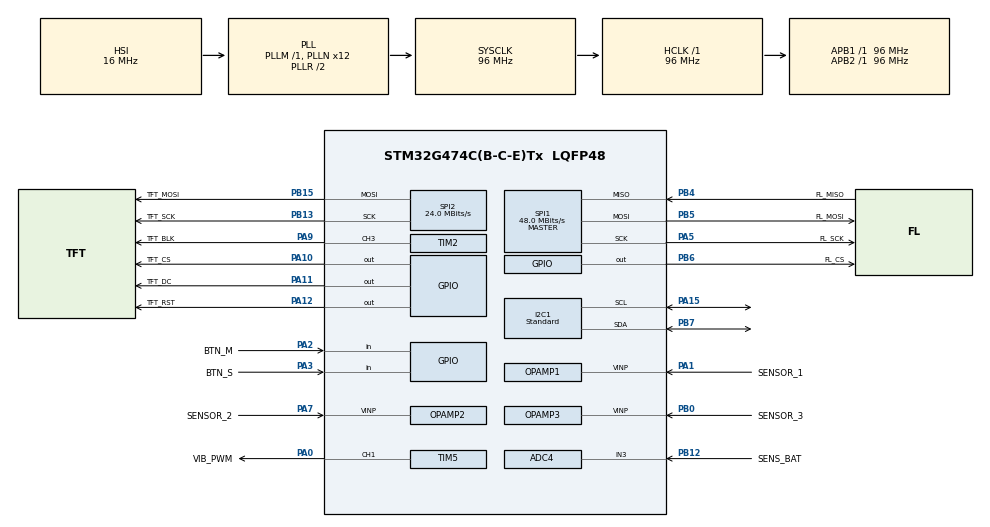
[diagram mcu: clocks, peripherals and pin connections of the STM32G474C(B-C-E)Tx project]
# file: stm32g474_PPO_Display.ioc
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ADC1.Channel-2\#ChannelRegularConversion=ADC_CHANNEL_VOPAMP1
ADC1.ContinuousConvMode=ENABLE
ADC1.DMAContinuousRequests=ENABLE
ADC1.EOCSelection=ADC_EOC_SEQ_CONV
ADC1.NbrOfConversionFlag=1
ADC1.OffsetNumber-2\#ChannelRegularConversion=ADC_OFFSET_NONE
ADC1.OversamplingMode=ENABLE
ADC1.Rank-2\#ChannelRegularConversion=1
ADC1.Ratio=ADC_OVERSAMPLING_RATIO_16
ADC1.RightBitShift=ADC_RIGHTBITSHIFT_4
ADC1.SamplingTime-2\#ChannelRegularConversion=ADC_SAMPLETIME_247CYCLES_5
ADC1.master=1
ADC2.Channel-0\#ChannelRegularConversion=ADC_CHANNEL_VOPAMP2
ADC2.ContinuousConvMode=ENABLE
ADC2.DMAContinuousRequests=ENABLE
ADC2.NbrOfConversionFlag=1
ADC2.OffsetNumber-0\#ChannelRegularConversion=ADC_OFFSET_NONE
ADC2.OversamplingMode=ENABLE
ADC2.Rank-0\#ChannelRegularConversion=1
ADC2.Ratio=ADC_OVERSAMPLING_RATIO_16
ADC2.RightBitShift=ADC_RIGHTBITSHIFT_4
ADC2.SamplingTime-0\#ChannelRegularConversion=ADC_SAMPLETIME_247CYCLES_5
ADC3.Channel-0\#ChannelRegularConversion=ADC_CHANNEL_VOPAMP3_ADC3
ADC3.ContinuousConvMode=ENABLE
ADC3.DMAContinuousRequests=ENABLE
ADC3.EOCSelection=ADC_EOC_SEQ_CONV
ADC3.NbrOfConversionFlag=1
ADC3.OffsetNumber-0\#ChannelRegularConversion=ADC_OFFSET_NONE
ADC3.OversamplingMode=ENABLE
ADC3.Rank-0\#ChannelRegularConversion=1
ADC3.Ratio=ADC_OVERSAMPLING_RATIO_16
ADC3.RightBitShift=ADC_RIGHTBITSHIFT_4
ADC3.SamplingTime-0\#ChannelRegularConversion=ADC_SAMPLETIME_247CYCLES_5
ADC3.master=1
ADC4.Channel-0\#ChannelRegularConversion=ADC_CHANNEL_VREFINT
ADC4.Channel-1\#ChannelRegularConversion=ADC_CHANNEL_3
ADC4.ContinuousConvMode=ENABLE
ADC4.DMAContinuousRequests=ENABLE
ADC4.EOCSelection=ADC_EOC_SEQ_CONV
ADC4.NbrOfConversion=2
ADC4.NbrOfConversionFlag=1
ADC4.OffsetNumber-0\#ChannelRegularConversion=ADC_OFFSET_NONE
ADC4.OffsetNumber-1\#ChannelRegularConversion=ADC_OFFSET_NONE
ADC4.OversamplingMode=ENABLE
ADC4.Rank-0\#ChannelRegularConversion=1
ADC4.Rank-1\#ChannelRegularConversion=2
ADC4.Ratio=ADC_OVERSAMPLING_RATIO_16
ADC4.RightBitShift=ADC_RIGHTBITSHIFT_4
ADC4.SamplingTime-0\#ChannelRegularConversion=ADC_SAMPLETIME_247CYCLES_5
ADC4.SamplingTime-1\#ChannelRegularConversion=ADC_SAMPLETIME_247CYCLES_5
Dma.ADC1.1.Direction=DMA_PERIPH_TO_MEMORY
Dma.ADC1.1.EventEnable=DISABLE
Dma.ADC1.1.Instance=DMA1_Channel4
Dma.ADC1.1.MemDataAlignment=DMA_MDATAALIGN_HALFWORD
Dma.ADC1.1.MemInc=DMA_MINC_ENABLE
Dma.ADC1.1.Mode=DMA_CIRCULAR
Dma.ADC1.1.PeriphDataAlignment=DMA_PDATAALIGN_HALFWORD
Dma.ADC1.1.PeriphInc=DMA_PINC_DISABLE
Dma.ADC1.1.Polarity=HAL_DMAMUX_REQ_GEN_RISING
Dma.ADC1.1.Priority=DMA_PRIORITY_LOW
Dma.ADC1.1.RequestNumber=1
Dma.ADC1.1.SignalID=NONE
Dma.ADC1.1.SyncEnable=DISABLE
Dma.ADC1.1.SyncPolarity=HAL_DMAMUX_SYNC_NO_EVENT
Dma.ADC1.1.SyncRequestNumber=1
Dma.ADC1.1.SyncSignalID=NONE
Dma.ADC2.2.Direction=DMA_PERIPH_TO_MEMORY
Dma.ADC2.2.EventEnable=DISABLE
Dma.ADC2.2.Instance=DMA1_Channel5
Dma.ADC2.2.MemDataAlignment=DMA_MDATAALIGN_HALFWORD
Dma.ADC2.2.MemInc=DMA_MINC_ENABLE
Dma.ADC2.2.Mode=DMA_CIRCULAR
Dma.ADC2.2.PeriphDataAlignment=DMA_PDATAALIGN_HALFWORD
Dma.ADC2.2.PeriphInc=DMA_PINC_DISABLE
Dma.ADC2.2.Polarity=HAL_DMAMUX_REQ_GEN_RISING
Dma.ADC2.2.Priority=DMA_PRIORITY_LOW
Dma.ADC2.2.RequestNumber=1
Dma.ADC2.2.SignalID=NONE
Dma.ADC2.2.SyncEnable=DISABLE
Dma.ADC2.2.SyncPolarity=HAL_DMAMUX_SYNC_NO_EVENT
Dma.ADC2.2.SyncRequestNumber=1
Dma.ADC2.2.SyncSignalID=NONE
Dma.ADC3.3.Direction=DMA_PERIPH_TO_MEMORY
Dma.ADC3.3.EventEnable=DISABLE
Dma.ADC3.3.Instance=DMA1_Channel6
Dma.ADC3.3.MemDataAlignment=DMA_MDATAALIGN_HALFWORD
Dma.ADC3.3.MemInc=DMA_MINC_ENABLE
Dma.ADC3.3.Mode=DMA_CIRCULAR
Dma.ADC3.3.PeriphDataAlignment=DMA_PDATAALIGN_HALFWORD
Dma.ADC3.3.PeriphInc=DMA_PINC_DISABLE
Dma.ADC3.3.Polarity=HAL_DMAMUX_REQ_GEN_RISING
Dma.ADC3.3.Priority=DMA_PRIORITY_LOW
Dma.ADC3.3.RequestNumber=1
Dma.ADC3.3.SignalID=NONE
Dma.ADC3.3.SyncEnable=DISABLE
Dma.ADC3.3.SyncPolarity=HAL_DMAMUX_SYNC_NO_EVENT
Dma.ADC3.3.SyncRequestNumber=1
Dma.ADC3.3.SyncSignalID=NONE
Dma.ADC4.4.Direction=DMA_PERIPH_TO_MEMORY
Dma.ADC4.4.EventEnable=DISABLE
Dma.ADC4.4.Instance=DMA1_Channel7
Dma.ADC4.4.MemDataAlignment=DMA_MDATAALIGN_HALFWORD
Dma.ADC4.4.MemInc=DMA_MINC_ENABLE
Dma.ADC4.4.Mode=DMA_CIRCULAR
Dma.ADC4.4.PeriphDataAlignment=DMA_PDATAALIGN_HALFWORD
Dma.ADC4.4.PeriphInc=DMA_PINC_DISABLE
Dma.ADC4.4.Polarity=HAL_DMAMUX_REQ_GEN_RISING
Dma.ADC4.4.Priority=DMA_PRIORITY_LOW
Dma.ADC4.4.RequestNumber=1
Dma.ADC4.4.SignalID=NONE
Dma.ADC4.4.SyncEnable=DISABLE
Dma.ADC4.4.SyncPolarity=HAL_DMAMUX_SYNC_NO_EVENT
Dma.ADC4.4.SyncRequestNumber=1
Dma.ADC4.4.SyncSignalID=NONE
Dma.Request0=SPI2_TX
Dma.Request1=ADC1
Dma.Request2=ADC2
Dma.Request3=ADC3
Dma.Request4=ADC4
Dma.SPI2_TX.0.Direction=DMA_MEMORY_TO_PERIPH
Dma.SPI2_TX.0.EventEnable=DISABLE
Dma.SPI2_TX.0.Instance=DMA1_Channel1
Dma.SPI2_TX.0.MemDataAlignment=DMA_MDATAALIGN_BYTE
Dma.SPI2_TX.0.MemInc=DMA_MINC_ENABLE
Dma.SPI2_TX.0.Mode=DMA_NORMAL
Dma.SPI2_TX.0.PeriphDataAlignment=DMA_PDATAALIGN_BYTE
Dma.SPI2_TX.0.PeriphInc=DMA_PINC_DISABLE
Dma.SPI2_TX.0.Polarity=HAL_DMAMUX_REQ_GEN_RISING
Dma.SPI2_TX.0.Priority=DMA_PRIORITY_MEDIUM
Dma.SPI2_TX.0.RequestNumber=1
Dma.SPI2_TX.0.SignalID=NONE
Dma.SPI2_TX.0.SyncEnable=DISABLE
Dma.SPI2_TX.0.SyncPolarity=HAL_DMAMUX_SYNC_NO_EVENT
Dma.SPI2_TX.0.SyncRequestNumber=1
Dma.SPI2_TX.0.SyncSignalID=NONE
I2C1.Analog_Filter=I2C_ANALOGFILTER_ENABLE
I2C1.I2C_Coeff_DF=0
I2C1.I2C_Speed_Mode=I2C_Standard
I2C1.Speed=100
I2C1.Timing=0x20B17DB6
IWDG.Prescaler=IWDG_PRESCALER_64
IWDG.Reload=2999
Mcu.Family=STM32G4
Mcu.Name=STM32G474C(B-C-E)Tx
Mcu.Package=LQFP48
NVIC.ADC1_2_IRQn=true\:0\:0\:false\:false\:true\:true\:true\:true
NVIC.ADC3_IRQn=true\:0\:0\:false\:false\:true\:true\:true\:true
NVIC.ADC4_IRQn=true\:0\:0\:false\:false\:true\:true\:true\:true
NVIC.DMA1_Channel1_IRQn=true\:0\:0\:false\:false\:true\:false\:true\:true
NVIC.DMA1_Channel4_IRQn=true\:0\:0\:false\:false\:true\:false\:true\:true
NVIC.DMA1_Channel5_IRQn=true\:0\:0\:false\:false\:true\:false\:true\:true
NVIC.DMA1_Channel6_IRQn=true\:0\:0\:false\:false\:true\:false\:true\:true
NVIC.DMA1_Channel7_IRQn=true\:0\:0\:false\:false\:true\:false\:true\:true
NVIC.I2C1_ER_IRQn=true\:1\:0\:true\:false\:true\:true\:true\:true
NVIC.I2C1_EV_IRQn=true\:1\:0\:true\:false\:true\:true\:true\:true
NVIC.PriorityGroup=NVIC_PRIORITYGROUP_4
NVIC.SPI2_IRQn=true\:0\:0\:false\:false\:true\:true\:true\:true
NVIC.TIM6_DAC_IRQn=true\:0\:0\:false\:false\:true\:true\:true\:true
OPAMP1.PgaGain=OPAMP_PGA_GAIN_16_OR_MINUS_15
OPAMP2.PgaGain=OPAMP_PGA_GAIN_16_OR_MINUS_15
OPAMP3.PgaGain=OPAMP_PGA_GAIN_16_OR_MINUS_15
PA0.GPIO_Label=VIB_PWM
PA0.GPIO_Speed=GPIO_SPEED_FREQ_VERY_HIGH
PA0.Signal=S_TIM5_CH1
PA1.GPIO_Label=SENSOR_1
PA1.Mode=PGA_Internally_Connected
PA1.Signal=OPAMP1_VINP
PA10.GPIO_Label=TFT_CS
PA10.GPIO_Speed=GPIO_SPEED_FREQ_VERY_HIGH
PA10.PinState=GPIO_PIN_SET
PA10.Signal=GPIO_Output
PA11.GPIO_Label=TFT_DC
PA11.GPIO_Speed=GPIO_SPEED_FREQ_VERY_HIGH
PA11.PinState=GPIO_PIN_SET
PA11.Signal=GPIO_Output
PA12.GPIO_Label=TFT_RST
PA12.GPIO_PuPd=GPIO_PULLUP
PA12.GPIO_Speed=GPIO_SPEED_FREQ_VERY_HIGH
PA12.PinState=GPIO_PIN_SET
PA12.Signal=GPIO_Output
PA13.Mode=Serial_Wire
PA13.Signal=SYS_JTMS-SWDIO
PA14.Mode=Serial_Wire
PA14.Signal=SYS_JTCK-SWCLK
PA15.GPIO_Mode=GPIO_MODE_AF_OD
PA15.GPIO_Pu=GPIO_NOPULL
PA15.GPIO_Speed=GPIO_SPEED_FREQ_LOW
PA15.Mode=I2C
PA15.Signal=I2C1_SCL
PA2.GPIO_Label=BTN_M
PA2.GPIO_Mode=GPIO_MODE_INPUT
PA2.GPIO_PuPd=GPIO_PULLDOWN
PA2.Signal=GPIO_Input
PA3.GPIO_Label=BTN_S
PA3.GPIO_PuPd=GPIO_PULLDOWN
PA3.Signal=GPIO_Input
PA5.GPIO_Label=FL_SCK
PA5.GPIO_Speed=GPIO_SPEED_FREQ_VERY_HIGH
PA5.Mode=Full_Duplex_Master
PA5.Signal=SPI1_SCK
PA7.GPIO_Label=SENSOR_2
PA7.Mode=PGA_Internally_Connected
PA7.Signal=OPAMP2_VINP
PA9.GPIO_Label=TFT_BLK
PA9.GPIO_Speed=GPIO_SPEED_FREQ_VERY_HIGH
PA9.Signal=S_TIM2_CH3
PB0.GPIO_Label=SENSOR_3
PB0.Mode=PGA_Internally_Connected
PB0.Signal=OPAMP3_VINP
PB12.GPIO_Label=SENS_BAT
PB12.Mode=IN3-Single-Ended
PB12.Signal=ADC4_IN3
PB13.GPIO_Label=TFT_SCK
PB13.GPIO_PuPd=GPIO_PULLDOWN
PB13.GPIO_Speed=GPIO_SPEED_FREQ_VERY_HIGH
PB13.Mode=TX_Only_Simplex_Unidirect_Master
PB13.Signal=SPI2_SCK
PB15.GPIO_Label=TFT_MOSI
PB15.GPIO_PuPd=GPIO_PULLUP
PB15.GPIO_Speed=GPIO_SPEED_FREQ_VERY_HIGH
PB15.Mode=TX_Only_Simplex_Unidirect_Master
PB15.Signal=SPI2_MOSI
PB4.GPIO_Label=FL_MISO
PB4.GPIO_Speed=GPIO_SPEED_FREQ_VERY_HIGH
PB4.Mode=Full_Duplex_Master
PB4.Signal=SPI1_MISO
PB5.GPIO_Label=FL_MOSI
PB5.GPIO_Speed=GPIO_SPEED_FREQ_VERY_HIGH
PB5.Mode=Full_Duplex_Master
PB5.Signal=SPI1_MOSI
PB6.GPIO_Label=FL_CS
PB6.GPIO_PuPd=GPIO_PULLUP
PB6.GPIO_Speed=GPIO_SPEED_FREQ_VERY_HIGH
PB6.PinState=GPIO_PIN_SET
PB6.Signal=GPIO_Output
PB7.GPIO_FM7=__NULL
PB7.GPIO_Mode=GPIO_MODE_AF_OD
PB7.GPIO_Pu=GPIO_NOPULL
PB7.GPIO_Speed=GPIO_SPEED_FREQ_LOW
PB7.Mode=I2C
PB7.Signal=I2C1_SDA
ProjectManager.HeapSize=0x200
ProjectManager.StackSize=0x400
ProjectManager.TargetToolchain=STM32CubeIDE
RCC.ADC12Freq_Value=96000000
RCC.ADC345Freq_Value=96000000
RCC.AHBFreq_Value=96000000
RCC.APB1Freq_Value=96000000
RCC.APB1TimFreq_Value=96000000
RCC.APB2Freq_Value=96000000
RCC.APB2TimFreq_Value=96000000
RCC.CortexFreq_Value=96000000
RCC.EXTERNAL_CLOCK_VALUE=12288000
RCC.HCLKFreq_Value=96000000
RCC.HSE_VALUE=8000000
RCC.HSI48_VALUE=48000000
RCC.HSI_VALUE=16000000
RCC.LSE_VALUE=32768
RCC.PLLN=12
RCC.SYSCLKFreq_VALUE=96000000
RCC.SYSCLKSource=RCC_SYSCLKSOURCE_PLLCLK
RCC.USBFreq_Value=96000000
RCC.VCOOutputFreq_Value=192000000
SH.S_TIM2_CH3.0=TIM2_CH3,PWM Generation3 CH3
SH.S_TIM5_CH1.0=TIM5_CH1,PWM Generation1 CH1
SPI1.BaudRatePrescaler=SPI_BAUDRATEPRESCALER_2
SPI1.CLKPhase=SPI_PHASE_2EDGE
SPI1.CLKPolarity=SPI_POLARITY_HIGH
SPI1.CalculateBaudRate=48.0 MBits/s
SPI1.DataSize=SPI_DATASIZE_8BIT
SPI1.Direction=SPI_DIRECTION_2LINES
SPI1.Mode=SPI_MODE_MASTER
SPI1.VirtualType=VM_MASTER
SPI2.BaudRatePrescaler=SPI_BAUDRATEPRESCALER_4
SPI2.CLKPhase=SPI_PHASE_2EDGE
SPI2.CLKPolarity=SPI_POLARITY_HIGH
SPI2.CalculateBaudRate=24.0 MBits/s
SPI2.DataSize=SPI_DATASIZE_8BIT
SPI2.Direction=SPI_DIRECTION_2LINES
SPI2.Mode=SPI_MODE_MASTER
SPI2.VirtualType=VM_MASTER
TIM2.AutoReloadPreload=TIM_AUTORELOAD_PRELOAD_ENABLE
TIM2.Channel-PWM\ Generation3\ CH3=TIM_CHANNEL_3
TIM2.PeriodNoDither=4799
TIM5.Channel-PWM\ Generation1\ CH1=TIM_CHANNEL_1
TIM6.AutoReloadPreload=TIM_AUTORELOAD_PRELOAD_ENABLE
TIM6.PeriodNoDither=65535
TIM6.Prescaler=95
VP_ADC1_OPAMP_INTERNAL1.Mode=IN-OPAMP1
VP_ADC2_OPAMP_INTERNAL2.Mode=IN-OPAMP2
VP_ADC3_OPAMP_INTERNAL3.Mode=IN-OPAMP3
VP_ADC4_Vref_Input.Mode=IN-Vrefint
VP_IWDG_VS_IWDG.Mode=IWDG_Activate
VP_SYS_VS_DBSignals.Mode=DisableDeadBatterySignals
VP_TIM1_VS_ClockSourceINT.Mode=Internal
VP_TIM2_VS_ClockSourceINT.Mode=Internal
VP_TIM3_VS_ClockSourceINT.Mode=Internal
VP_TIM5_VS_ClockSourceINT.Mode=Internal
VP_TIM6_VS_ClockSourceINT.Mode=Enable_Timer
VREF+.Mode=InternalMode
VREF+.Signal=VREFBUF_OUT
board=custom

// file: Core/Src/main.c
/* USER CODE BEGIN Header */
/**
  ******************************************************************************
  * @file           : main.c
  * @brief          : Main program body
  ******************************************************************************
  * @attention
  *
  * Copyright (c) 2026 STMicroelectronics.
  * All rights reserved.
  *
  * This software is licensed under terms that can be found in the LICENSE file
  * in the root directory of this software component.
  * If no LICENSE file comes with this software, it is provided AS-IS.
  *
  ******************************************************************************
  */
/* USER CODE END Header */
#include "main.h"

/* USER CODE BEGIN Includes */
#include <stdatomic.h>
#include <stdbool.h>
#include "stm32g4xx_ll_adc.h"
#include "stm32g4xx.h"
#include "sensor.h"
#include "lvgl.h"
#include "st7789v.h"
#include "screen_manager.h"
#include "button.h"
#include "flash_storage.h"
#include "settings_storage.h"
#include "ext_flash_storage.h"
#include "drift_tracker.h"
#include "ms5837.h"
#include "w25q128.h"
#include "warning.h"
#include "dive_log.h"

/* USER CODE END Includes */

/* USER CODE BEGIN PTD */

// Display configuration (landscape orientation)
#define LCD_H_RES       320
#define LCD_V_RES       240
#define DISP_BUF_LINES  20  // Number of lines in partial refresh buffer

// LVGL display buffer - single buffer for partial refresh mode
// RGB565 = 2 bytes per pixel, 10 lines = 320 * 10 * 2 = 6400 bytes
static lv_color_t disp_buf1[LCD_H_RES * DISP_BUF_LINES] = {0};
static lv_color_t disp_buf2[LCD_H_RES * DISP_BUF_LINES] = {0};

// LVGL v8 display driver structures (must be global for ISR access from other files)
static lv_disp_draw_buf_t disp_draw_buf;
lv_disp_drv_t disp_drv;  // Non-static so ISR can access it

static volatile uint16_t ADC1_VAL[1];   // SENSOR1 via VOPAMP1
static volatile uint16_t ADC2_VAL[1];   // SENSOR2 via VOPAMP2
static volatile uint16_t ADC3_VAL[1];   // SENSOR3 via VOPAMP3
static volatile uint16_t ADC4_VAL[2];   // [0]=VREFINT  [1]=BAT (PB12)
static volatile atomic_bool g_adc1_new = false;
static volatile atomic_bool g_adc2_new = false;
static volatile atomic_bool g_adc3_new = false;
static volatile atomic_bool g_adc4_new = false;

// Elapsed time counter (seconds since boot)
uint32_t g_elapsed_time_sec = 0;
/* Bottom timer start depth in mm. 1000 mm = 1 m. Change for bench testing. */
#define BOTTOM_TIMER_START_DEPTH_MM  1000

static volatile uint32_t g_ms = 0; // ms since boot (from 1kHz tick)
static bool g_debugger_connected = false; // cached once at boot; DHCSR doesn't change at runtime

static volatile atomic_bool g_flag_1hz = false;
static volatile atomic_bool g_flag_5ms = false;
static volatile atomic_bool g_flag_20ms = false;
static volatile atomic_bool g_flag_10s = false;  // NEW: 10-second flag for drift tracking

/**
 * Gamma 2.2 Lookup Table for Backlight PWM
 * Clock: 48 MHz | Prescaler: 0 | ARR: 4799 (10 kHz PWM)
 * Index 0 = OFF, Index 1 = 10% ... Index 10 = 100%
 * Provides perceptually linear brightness control
 */
const uint16_t backlight_gamma_lut[11] = {
      0,   // 0%   (OFF)
     30,   // 10%
    139,   // 20%
    339,   // 30%
    639,   // 40%
   1044,   // 50%
   1561,   // 60%
   2190,   // 70%
   2937,   // 80%
   3808,   // 90%
   4799    // 100% (MAX)
};

uint32_t vref_effective_mv = 3300;     // == VDDA in mV

// Debug: Store VREFINT raw reading for troubleshooting
uint16_t vrefint_raw_debug = 0;

// MS5837 pressure sensor calibration and data
static ms5837_calib_t ms5837_calib;  // Factory calibration coefficients
static ms5837_data_t ms5837_data;    // Latest pressure/temperature measurement
static volatile bool ms5837_initialized = false;  // Initialization status flag
static bool ms5837_surface_set = false;           // True after first reading captures actual ambient

/* MS5837 DMA-driven measurement FSM */
typedef enum {
    MS5837_FSM_IDLE = 0,
    MS5837_FSM_D2_CONV_TX,   /* D2 conversion command TX in progress */
    MS5837_FSM_WAIT_D2,
    MS5837_FSM_D2_READ_TX,
    MS5837_FSM_D2_READ_RX,
    MS5837_FSM_D1_CMD_TX,
    MS5837_FSM_WAIT_D1,
    MS5837_FSM_D1_READ_TX,
    MS5837_FSM_D1_READ_RX,
    MS5837_FSM_CALCULATE,
} ms5837_fsm_t;

static volatile ms5837_fsm_t  ms5837_fsm        = MS5837_FSM_IDLE;
static volatile uint32_t      ms5837_conv_start = 0;
static volatile uint32_t      ms5837_raw_D1     = 0;
static volatile uint32_t      ms5837_raw_D2     = 0;
static volatile uint32_t      ms5837_last_meas  = 0;
/* Static buffers required: DMA accesses them after function returns */
static uint8_t       ms5837_tx_buf[1]  = {0};
static uint8_t       ms5837_rx_buf[3]  = {0, 0, 0};

/* USER CODE END PTD */

ADC_HandleTypeDef hadc1;
ADC_HandleTypeDef hadc2;
ADC_HandleTypeDef hadc3;
ADC_HandleTypeDef hadc4;
DMA_HandleTypeDef hdma_adc1;
DMA_HandleTypeDef hdma_adc2;
DMA_HandleTypeDef hdma_adc3;
DMA_HandleTypeDef hdma_adc4;

I2C_HandleTypeDef hi2c1;

IWDG_HandleTypeDef hiwdg;

OPAMP_HandleTypeDef hopamp1;
OPAMP_HandleTypeDef hopamp2;
OPAMP_HandleTypeDef hopamp3;

SPI_HandleTypeDef hspi1;
SPI_HandleTypeDef hspi2;
DMA_HandleTypeDef hdma_spi2_tx;

TIM_HandleTypeDef htim1;
TIM_HandleTypeDef htim2;
TIM_HandleTypeDef htim3;
TIM_HandleTypeDef htim5;
TIM_HandleTypeDef htim6;

void SystemClock_Config(void);
static void MX_GPIO_Init(void);
static void MX_DMA_Init(void);
static void MX_ADC1_Init(void);
static void MX_ADC2_Init(void);
static void MX_ADC3_Init(void);
static void MX_ADC4_Init(void);
static void MX_I2C1_Init(void);
static void MX_OPAMP1_Init(void);
static void MX_OPAMP2_Init(void);
static void MX_OPAMP3_Init(void);
static void MX_SPI1_Init(void);
static void MX_SPI2_Init(void);
static void MX_TIM2_Init(void);
static void MX_TIM5_Init(void);
static void MX_TIM1_Init(void);
static void MX_TIM6_Init(void);
static void MX_TIM3_Init(void);
static void MX_IWDG_Init(void);
/* USER CODE BEGIN PFP */
void vibro_motor_test(void);

static void scheduler_tick_1kHz(void);
static void scheduler_tick_5ms(void);
static void scheduler_tick_20ms(void);
static void scheduler_tick_10s(void);

void system_shutdown(void);  // Power management

static bool emulate_profile = false;
static bool emulate_descend = true;
static int8_t emulate_depth = 0;

/* USER CODE END PFP */

/* USER CODE BEGIN 0 */

uint8_t isDebuggerConnected(void) {
    if (CoreDebug->DHCSR & CoreDebug_DHCSR_C_DEBUGEN_Msk) {
        return 1; // Debugger is attached
    }
    return 0; // Running standalone
}

void HAL_TIM_PeriodElapsedCallback(TIM_HandleTypeDef *htim) {
	if (htim->Instance == TIM6) {
		scheduler_tick_1kHz();
		scheduler_tick_5ms();
		scheduler_tick_20ms();
		scheduler_tick_10s();  // NEW: 10-second scheduler for drift tracking
	}
}

static void scheduler_tick_5ms(void){
		static uint32_t t1 = 0;
		if ((g_ms - t1) >= 5) {
			t1 = g_ms;
			atomic_store(&g_flag_5ms, true);
		}
}

static void scheduler_tick_20ms(void) {
	static uint32_t t = 0;
	if ((g_ms - t) >= 20) {
		t = g_ms;
		atomic_store(&g_flag_20ms, true);
	}
}

static void scheduler_tick_1kHz(void) {
	g_ms++;

	// 1 Hz: every 1000 ms
	static uint32_t t1 = 0;
	if ((g_ms - t1) >= 1000) {
		t1 = g_ms;
		atomic_store(&g_flag_1hz, true);
	}
}

static void scheduler_tick_10s(void) {
	static uint32_t t = 0;
	if ((g_ms - t) >= 10000) {  // 10 seconds = 10000 ms
		t = g_ms;
		atomic_store(&g_flag_10s, true);
	}
}

void HAL_ADC_ConvCpltCallback(ADC_HandleTypeDef *hadc) {
    if (hadc->Instance == ADC1) atomic_store(&g_adc1_new, true);
    if (hadc->Instance == ADC2) atomic_store(&g_adc2_new, true);
    if (hadc->Instance == ADC3) atomic_store(&g_adc3_new, true);
    if (hadc->Instance == ADC4) atomic_store(&g_adc4_new, true);
}

void HAL_SPI_TxCpltCallback(SPI_HandleTypeDef *hspi)
{
    if (hspi->Instance == SPI2) {
    //    HAL_GPIO_WritePin(LCD_CS_GPIO_Port, LCD_CS_Pin, GPIO_PIN_SET);
     //   my_disp_bus_busy = 0;

        // v8 API: pass driver struct pointer
        lv_disp_flush_ready(&disp_drv);
    }
}

/**
 * @brief System shutdown - Stop peripherals and enter Stop1 mode
 * @note Wakes on PA2 (BTN_M) via EXTI2 (already enabled by MX_GPIO_Init).
 *       GPIO state is retained in Stop1. On wake: full system reset for clean boot.
 *       IWDG continues in Stop1 — refreshed here to give the full ~6s window.
 *       Set option byte IWDG_STOP=0 in CubeProgrammer to freeze IWDG in Stop mode.
 */
void system_shutdown(void) {
    // Step 1: Put display to sleep via SPI (must happen before peripherals stop)
    // DISPOFF turns off panel output; SLPIN enters sleep (screen goes dark).
    // GPIO state is retained in Stop1 so CS/RST held here remain valid.
    ST7789V_SendCmd(ST7789_DISPOFF, NULL, 0);
    HAL_Delay(20);
    ST7789V_SendCmd(ST7789_SLPIN, NULL, 0);
    HAL_Delay(120);  // Required post-SLPIN settling per ST7789V datasheet
    HAL_GPIO_WritePin(TFT_CS_GPIO_Port,  TFT_CS_Pin,  GPIO_PIN_SET);   // Deselect
    HAL_GPIO_WritePin(TFT_RST_GPIO_Port, TFT_RST_Pin, GPIO_PIN_SET);   // Not in reset

    // Step 2: Turn off LCD backlight (TIM2_CH3 on TFT_BLK/PA9)
    HAL_TIM_PWM_Stop(&htim2, TIM_CHANNEL_3);
    __HAL_TIM_SET_COMPARE(&htim2, TIM_CHANNEL_3, 0);
    GPIO_InitTypeDef GPIO_InitStruct = {0};
    GPIO_InitStruct.Pin   = TFT_BLK_Pin;
    GPIO_InitStruct.Mode  = GPIO_MODE_OUTPUT_PP;
    GPIO_InitStruct.Pull  = GPIO_NOPULL;
    GPIO_InitStruct.Speed = GPIO_SPEED_FREQ_LOW;
    HAL_GPIO_Init(TFT_BLK_GPIO_Port, &GPIO_InitStruct);
    HAL_GPIO_WritePin(TFT_BLK_GPIO_Port, TFT_BLK_Pin, GPIO_PIN_RESET);

    // Step 3: Stop all peripherals
    HAL_ADC_Stop_DMA(&hadc1);
    HAL_ADC_Stop_DMA(&hadc2);
    HAL_ADC_Stop_DMA(&hadc3);
    HAL_ADC_Stop_DMA(&hadc4);
    HAL_TIM_Base_Stop_IT(&htim6);  // 1kHz scheduler
    HAL_TIM_Base_Stop(&htim3);     // ADC2 trigger
    HAL_OPAMP_Stop(&hopamp1);
    HAL_OPAMP_Stop(&hopamp2);
    HAL_OPAMP_Stop(&hopamp3);

    // Step 4: Clear pending BTN_M (PA2/EXTI2) flag — EXTI2_IRQn already enabled
    __HAL_PWR_CLEAR_FLAG(PWR_FLAG_WU);
    __HAL_GPIO_EXTI_CLEAR_IT(BTN_M_Pin);

    // Step 5: Enter Stop1 mode (~2 µA)
    // Refresh IWDG for full ~6s window (freeze with IWDG_STOP=0 option byte for indefinite sleep)
    HAL_IWDG_Refresh(&hiwdg);
    HAL_SuspendTick();
    HAL_PWREx_EnterSTOP1Mode(PWR_STOPENTRY_WFI);

    // Step 6: Wake-up — restore clocks and do a clean reset
    SystemClock_Config();
    HAL_ResumeTick();
    NVIC_SystemReset();
}

/**
 * @brief MS5837 main-loop tick — handles timer-wait states and CALCULATE.
 * All other state transitions happen inside DMA callbacks (ISR context).
 */
static void ms5837_fsm_tick(void)
{
    if (!ms5837_initialized) return;

    switch (ms5837_fsm) {

        case MS5837_FSM_IDLE:
            if ((g_ms - ms5837_last_meas) >= 1000U) {
                ms5837_tx_buf[0] = MS5837_CMD_CONV_D2 + MS5837_OSR_4096;
                if (HAL_I2C_Master_Transmit_IT(&hi2c1,
                        (uint16_t)(MS5837_I2C_ADDR << 1),
                        ms5837_tx_buf, 1U) == HAL_OK) {
                    ms5837_fsm = MS5837_FSM_D2_CONV_TX;  /* TxCplt advances to WAIT_D2 */
                } else {
                    ms5837_last_meas = g_ms;  /* back-off 1 s on bus error */
                }
            }
            break;

        case MS5837_FSM_WAIT_D2:
            if ((g_ms - ms5837_conv_start) >= MS5837_CONV_DELAY_4096) {
                ms5837_tx_buf[0] = MS5837_CMD_ADC_READ;
                if (HAL_I2C_Master_Transmit_IT(&hi2c1,
                        (uint16_t)(MS5837_I2C_ADDR << 1),
                        ms5837_tx_buf, 1U) == HAL_OK) {
                    ms5837_fsm = MS5837_FSM_D2_READ_TX;
                }
            }
            break;

        case MS5837_FSM_WAIT_D1:
            if ((g_ms - ms5837_conv_start) >= MS5837_CONV_DELAY_4096) {
                ms5837_tx_buf[0] = MS5837_CMD_ADC_READ;
                if (HAL_I2C_Master_Transmit_IT(&hi2c1,
                        (uint16_t)(MS5837_I2C_ADDR << 1),
                        ms5837_tx_buf, 1U) == HAL_OK) {
                    ms5837_fsm = MS5837_FSM_D1_READ_TX;
                }
            }
            break;

        case MS5837_FSM_CALCULATE:
            ms5837_calculate(&ms5837_calib, ms5837_raw_D1, ms5837_raw_D2, &ms5837_data);
            {
                int32_t scaled_p = ms5837_data.pressure_mbar * 20;
                /* Four pressure fields written from main-loop context only.
                 * If any field is ever read from ISR, wrap in __disable_irq()/__enable_irq(). */
                sensor_data.pressure.pressure_mbar = scaled_p;
                if (!ms5837_surface_set) {
                    /* Use actual ambient only if plausible surface pressure.
                     * 108300 Pa = 1083 mbar, highest sea-level pressure ever recorded.
                     * Anything above means device restarted underwater — keep sea-level default. */
                    if (scaled_p <= 108300) {
                        sensor_data.pressure.surface_pressure_mbar = scaled_p;
                    }
                    ms5837_surface_set = true;
                }
                sensor_data.pressure.temperature_c =
                    (int16_t)(ms5837_data.temperature_c100 / 100);
                sensor_data.pressure.depth_mm = (!emulate_profile)?
                    pressure_sensor_calculate_depth_mm(
                        scaled_p, sensor_data.pressure.surface_pressure_mbar):emulate_depth*1000;
                sensor_data.pressure.pressure_valid = true;
            }
            ms5837_last_meas = g_ms;
            ms5837_fsm = MS5837_FSM_IDLE;
            break;

        default:
            break;  /* TX/RX states: DMA in progress, nothing to do */
    }
}

void HAL_I2C_MasterTxCpltCallback(I2C_HandleTypeDef *hi2c)
{
    if (hi2c->Instance != I2C1) return;

    switch (ms5837_fsm) {
        case MS5837_FSM_D2_CONV_TX:
            /* D2 conversion command sent — start conversion timer */
            ms5837_conv_start = g_ms;
            ms5837_fsm = MS5837_FSM_WAIT_D2;
            break;

        case MS5837_FSM_D2_READ_TX:
            /* ADC read command for D2 sent — start 3-byte IT RX */
            if (HAL_I2C_Master_Receive_IT(hi2c,
                    (uint16_t)(MS5837_I2C_ADDR << 1), ms5837_rx_buf, 3U) == HAL_OK) {
                ms5837_fsm = MS5837_FSM_D2_READ_RX;
            } else {
                ms5837_fsm = MS5837_FSM_IDLE;
                ms5837_last_meas = g_ms;
            }
            break;

        case MS5837_FSM_D1_CMD_TX:
            /* D1 conversion command sent — start conversion timer */
            ms5837_conv_start = g_ms;
            ms5837_fsm = MS5837_FSM_WAIT_D1;
            break;

        case MS5837_FSM_D1_READ_TX:
            /* ADC read command for D1 sent — start 3-byte IT RX */
            if (HAL_I2C_Master_Receive_IT(hi2c,
                    (uint16_t)(MS5837_I2C_ADDR << 1), ms5837_rx_buf, 3U) == HAL_OK) {
                ms5837_fsm = MS5837_FSM_D1_READ_RX;
            } else {
                ms5837_fsm = MS5837_FSM_IDLE;
                ms5837_last_meas = g_ms;
            }
            break;

        default:
            break;
    }
}

void HAL_I2C_MasterRxCpltCallback(I2C_HandleTypeDef *hi2c)
{
    if (hi2c->Instance != I2C1) return;

    switch (ms5837_fsm) {
        case MS5837_FSM_D2_READ_RX:
            /* Save D2 raw ADC value */
            ms5837_raw_D2 = ((uint32_t)ms5837_rx_buf[0] << 16)
                          | ((uint32_t)ms5837_rx_buf[1] << 8)
                          |  (uint32_t)ms5837_rx_buf[2];
            /* Start D1 conversion command */
            ms5837_tx_buf[0] = MS5837_CMD_CONV_D1 + MS5837_OSR_4096;
            if (HAL_I2C_Master_Transmit_IT(hi2c,
                    (uint16_t)(MS5837_I2C_ADDR << 1),
                    ms5837_tx_buf, 1U) == HAL_OK) {
                ms5837_fsm = MS5837_FSM_D1_CMD_TX;
            } else {
                ms5837_fsm = MS5837_FSM_IDLE;
                ms5837_last_meas = g_ms;
            }
            break;

        case MS5837_FSM_D1_READ_RX:
            /* Save D1 raw ADC value — hand off to main loop for calculation */
            ms5837_raw_D1 = ((uint32_t)ms5837_rx_buf[0] << 16)
                          | ((uint32_t)ms5837_rx_buf[1] << 8)
                          |  (uint32_t)ms5837_rx_buf[2];
            ms5837_fsm = MS5837_FSM_CALCULATE;
            break;

        default:
            break;
    }
}

void HAL_I2C_ErrorCallback(I2C_HandleTypeDef *hi2c)
{
    if (hi2c->Instance != I2C1) return;
    /* Any I2C error (NACK, BERR, ARLO, TIMEOUT) resets the FSM.
       hi2c->State is already READY when HAL calls this. */
    ms5837_fsm = MS5837_FSM_IDLE;
    ms5837_last_meas = g_ms;  /* back off 1 s before next attempt */
}

/* USER CODE END 0 */

int main(void)
{

  /* MCU Configuration--------------------------------------------------------*/

  /* Reset of all peripherals, Initializes the Flash interface and the Systick. */
  HAL_Init();

  /* Configure the system clock */
  SystemClock_Config();

  /* Initialize all configured peripherals */
  MX_GPIO_Init();
  MX_DMA_Init();
  MX_ADC1_Init();
  MX_ADC2_Init();
  MX_ADC3_Init();
  MX_ADC4_Init();
  MX_I2C1_Init();
  MX_OPAMP1_Init();
  MX_OPAMP2_Init();
  MX_OPAMP3_Init();
  MX_SPI1_Init();
  MX_SPI2_Init();
  MX_TIM2_Init();
  MX_TIM5_Init();
  MX_TIM1_Init();
  MX_TIM6_Init();
  MX_TIM3_Init();
  MX_IWDG_Init();
  /* USER CODE BEGIN 2 */

  g_debugger_connected = (isDebuggerConnected() != 0);

  /* DEBUG: uncomment to test vibro motor hardware before main loop */
//  vibro_motor_test();

  // NOTE: Do NOT lock OPAMPs yet - need to change gain for offset calibration

  	HAL_ADCEx_Calibration_Start(&hadc1, ADC_SINGLE_ENDED);
  	HAL_ADCEx_Calibration_Start(&hadc2, ADC_SINGLE_ENDED);
  	HAL_ADCEx_Calibration_Start(&hadc3, ADC_SINGLE_ENDED);
  	HAL_ADCEx_Calibration_Start(&hadc4, ADC_SINGLE_ENDED);

  	HAL_OPAMP_Start(&hopamp1);
  	HAL_OPAMP_Start(&hopamp2);
  	HAL_OPAMP_Start(&hopamp3);

  	HAL_OPAMP_Lock(&hopamp2);
  	HAL_OPAMP_Lock(&hopamp3);
  	HAL_OPAMP_Lock(&hopamp1);

  	HAL_TIM_Base_Start_IT(&htim6);
  	//HAL_TIM_Base_Start(&htim2);
  	// HAL_ADC_Start_IT(&hadc2);
  //	HAL_TIM_PWM_Start(&htim2, TIM_CHANNEL_1);
  	HAL_ADC_Start_DMA(&hadc1, (uint32_t*) ADC1_VAL, 1);
  	HAL_ADC_Start_DMA(&hadc2, (uint32_t*) ADC2_VAL, 1);
  	HAL_ADC_Start_DMA(&hadc3, (uint32_t*) ADC3_VAL, 1);
  	HAL_ADC_Start_DMA(&hadc4, (uint32_t*) ADC4_VAL, 2);

  	w25q128_init(&hspi1);     /* CS_HIGH + software reset before first use */

  	sensor_init();
  	pressure_sensor_init();  // Initialize pressure sensor data structure

  	// Initialize MS5837 pressure sensor (blocking, one-time at boot — PROM only)
  	// First measurement comes from the DMA FSM within ~1s
  	if (ms5837_init(&hi2c1, &ms5837_calib, &ms5837_data) == MS5837_OK) {
  	    ms5837_initialized = true;
  	} else {
  	    sensor_data.pressure.pressure_valid = false; /* prevent phantom depth timer on sensor fault */
  	}

  	/* Initialize external flash storage (W25Q128 + calibration log scan) */
  	ext_flash_storage_init(&hspi1);

  	/* Initialize dive log (metadata ping-pong recovery + write pointer scan) */
  	dive_log_init(&hspi1);

  	// DIAGNOSTIC: Uncomment next line to erase settings and start fresh
  	// settings_erase();

  	// Load settings from flash (use defaults if not found)
  	if (!settings_load((settings_data_t*)&sensor_data.settings)) {
  		settings_init_defaults((settings_data_t*)&sensor_data.settings);
  	}
  	// Validate loaded settings (clamp to valid ranges)

  	settings_validate((settings_data_t*)&sensor_data.settings);

  	// Apply LCD brightness via PWM (TIM2 CH1 on PA15) with gamma correction
  	uint8_t brightness = sensor_data.settings.lcd_brightness;
  	/* brightness valid range 0–100 from settings_validate(); gamma_index 0–10.
  	 * Clamp guards against invalid stored settings (e.g. brightness=255 → gamma_index=25). */
  	uint8_t gamma_index = brightness / 10;  // 10% → index 1, 100% → index 10
  	if (gamma_index > 10) gamma_index = 10;
  	uint16_t pwm_value = backlight_gamma_lut[gamma_index];

  	// Set compare value before starting PWM
  	__HAL_TIM_SET_COMPARE(&htim2, TIM_CHANNEL_3, pwm_value);

  	// Start PWM output
  	if (HAL_TIM_PWM_Start(&htim2, TIM_CHANNEL_3) != HAL_OK) {
  		Error_Handler();
  	}

  		// Initialize ST7789V LCD hardware
  		ST7789V_Init();
  		// Backlight controlled by TIM2 PWM (see above)

  		// Initialize LVGL
  		lv_init();

  		// v8: Initialize draw buffer
  		lv_disp_draw_buf_init(&disp_draw_buf, disp_buf1, disp_buf2,
  		                       LCD_H_RES * DISP_BUF_LINES);

  		// v8: Initialize and register display driver
  		lv_disp_drv_init(&disp_drv);
  		disp_drv.hor_res = LCD_H_RES;
  		disp_drv.ver_res = LCD_V_RES;
  		disp_drv.flush_cb = ST7789V_Flush_Cb;
  		disp_drv.draw_buf = &disp_draw_buf;

  		lv_disp_t *disp = lv_disp_drv_register(&disp_drv);
  		if (disp == NULL) { Error_Handler(); }
  		ST7789V_SetDisplay(disp);

  		// v8: lv_scr_act() instead of lv_screen_active()
  	//	lv_obj_t *screen = lv_scr_act();
  	//	lv_obj_set_style_bg_color(screen, lv_color_black(), 0);
  		//lv_obj_set_style_bg_opa(screen, LV_OPA_COVER, 0);

  		// Initialize button handling
  		button_init();

  		// Initialize screen manager (loads startup screen)
  		screen_manager_init();

  		// Trigger initial render
  		lv_timer_handler();

  /* USER CODE END 2 */

  /* Infinite loop */
	while (1) {

    /* USER CODE BEGIN 3 */

		if (atomic_exchange(&g_flag_5ms, false)) {
			ms5837_fsm_tick();
			lv_timer_handler();
			vibro_tick_5ms();
		}

		if (atomic_exchange(&g_flag_20ms, false)) {
			// button_poll() removed - buttons now use EXTI interrupt
			btn_event_t evt = button_get_event();
			if (evt != BTN_NONE) {
				screen_manager_handle_button(evt);
			}
		}

		if (atomic_exchange(&g_adc1_new, false)) {

			sensor_data_update(SENSOR1, ADC1_VAL[0]);

		}

		if (atomic_exchange(&g_adc2_new, false)) {

			sensor_data_update(SENSOR2, ADC2_VAL[0]);

		}

		if (atomic_exchange(&g_adc3_new, false)) {

			sensor_data_update(SENSOR3, ADC3_VAL[0]);

		}

		if (atomic_exchange(&g_adc4_new, false)) {

			/* Copy both DMA values atomically — ADC4 DMA runs in circular mode;
			 * reading [0] then [1] risks a torn pair across a half-transfer.
			 * ADC1–3 use single-element arrays: each DMA write is one 16-bit
			 * store (atomic on Cortex-M4), so no masking is needed there. */
			__disable_irq();
			uint16_t adc4_vref = ADC4_VAL[0];
			uint16_t adc4_bat  = ADC4_VAL[1];
			__enable_irq();
			sensor_data_update(REFERENCE, adc4_vref);
			sensor_data_update(BAT, adc4_bat);

		}

		if (atomic_exchange(&g_flag_1hz, false)) {
			HAL_IWDG_Refresh(&hiwdg);
			/* Bottom timer: advance only when depth >= threshold */
			if (sensor_data.pressure.pressure_valid
					&& sensor_data.pressure.depth_mm
							>= BOTTOM_TIMER_START_DEPTH_MM) {
				g_elapsed_time_sec++;
			}
			/* Reset bottom timer when dive ends so next dive starts from 0 */
			static bool prev_dive_active = false;
			bool cur_dive_active = dive_log_is_active();
			if (prev_dive_active && !cur_dive_active) {
				g_elapsed_time_sec = 0;
			}
			prev_dive_active = cur_dive_active;
			screen_manager_update();
			dive_log_tick_1hz(g_elapsed_time_sec);
			/* Auto-shutdown: battery < 10% for 3 consecutive seconds */
			static uint8_t low_bat_count = 0;
			if (sensor_data.battery_percentage < 10U
					&& !g_debugger_connected) {
				low_bat_count++;
				if (low_bat_count >= 3U) {
					HAL_Delay(500);
					system_shutdown();
				}
			} else {
				low_bat_count = 0;
			}
		}

		if (atomic_exchange(&g_flag_10s, false)) {

			if (emulate_profile){
				emulate_depth = (emulate_descend) ? (int8_t)(emulate_depth + 2) : (int8_t)(emulate_depth - 2);
				if (emulate_depth > 20)  emulate_descend = false;
				if (emulate_depth<0) emulate_profile = false;
			}
			// Sample PPO for drift tracking (every 10 seconds)
			for (int i = 0; i < (SENSOR_COUNT - 2); i++) {
				if (sensor_data.s_valid[i]) {

					drift_tracker_sample(&sensor_data.drift[i],
							sensor_data.o2_s_ppo[i]);

				}
			}
		}

		if (!g_debugger_connected) {
			__WFI();
		}
	}
  /* USER CODE END 3 */
}

void SystemClock_Config(void)
{
  RCC_OscInitTypeDef RCC_OscInitStruct = {0};
  RCC_ClkInitTypeDef RCC_ClkInitStruct = {0};

  /** Configure the main internal regulator output voltage
  */
  HAL_PWREx_ControlVoltageScaling(PWR_REGULATOR_VOLTAGE_SCALE1);

  /** Initializes the RCC Oscillators according to the specified parameters
  * in the RCC_OscInitTypeDef structure.
  */
  RCC_OscInitStruct.OscillatorType = RCC_OSCILLATORTYPE_HSI|RCC_OSCILLATORTYPE_LSI;
  RCC_OscInitStruct.HSIState = RCC_HSI_ON;
  RCC_OscInitStruct.HSICalibrationValue = RCC_HSICALIBRATION_DEFAULT;
  RCC_OscInitStruct.LSIState = RCC_LSI_ON;
  RCC_OscInitStruct.PLL.PLLState = RCC_PLL_ON;
  RCC_OscInitStruct.PLL.PLLSource = RCC_PLLSOURCE_HSI;
  RCC_OscInitStruct.PLL.PLLM = RCC_PLLM_DIV1;
  RCC_OscInitStruct.PLL.PLLN = 12;
  RCC_OscInitStruct.PLL.PLLP = RCC_PLLP_DIV2;
  RCC_OscInitStruct.PLL.PLLQ = RCC_PLLQ_DIV2;
  RCC_OscInitStruct.PLL.PLLR = RCC_PLLR_DIV2;
  if (HAL_RCC_OscConfig(&RCC_OscInitStruct) != HAL_OK)
  {
    Error_Handler();
  }

  /** Initializes the CPU, AHB and APB buses clocks
  */
  RCC_ClkInitStruct.ClockType = RCC_CLOCKTYPE_HCLK|RCC_CLOCKTYPE_SYSCLK
                              |RCC_CLOCKTYPE_PCLK1|RCC_CLOCKTYPE_PCLK2;
  RCC_ClkInitStruct.SYSCLKSource = RCC_SYSCLKSOURCE_PLLCLK;
  RCC_ClkInitStruct.AHBCLKDivider = RCC_SYSCLK_DIV1;
  RCC_ClkInitStruct.APB1CLKDivider = RCC_HCLK_DIV1;
  RCC_ClkInitStruct.APB2CLKDivider = RCC_HCLK_DIV1;

  if (HAL_RCC_ClockConfig(&RCC_ClkInitStruct, FLASH_LATENCY_3) != HAL_OK)
  {
    Error_Handler();
  }
}

static void MX_ADC1_Init(void)
{

  ADC_MultiModeTypeDef multimode = {0};
  ADC_ChannelConfTypeDef sConfig = {0};

  /** Common config
  */
  hadc1.Instance = ADC1;
  hadc1.Init.ClockPrescaler = ADC_CLOCK_SYNC_PCLK_DIV2;
  hadc1.Init.Resolution = ADC_RESOLUTION_12B;
  hadc1.Init.DataAlign = ADC_DATAALIGN_RIGHT;
  hadc1.Init.GainCompensation = 0;
  hadc1.Init.ScanConvMode = ADC_SCAN_DISABLE;
  hadc1.Init.EOCSelection = ADC_EOC_SEQ_CONV;
  hadc1.Init.LowPowerAutoWait = DISABLE;
  hadc1.Init.ContinuousConvMode = ENABLE;
  hadc1.Init.NbrOfConversion = 1;
  hadc1.Init.DiscontinuousConvMode = DISABLE;
  hadc1.Init.ExternalTrigConv = ADC_SOFTWARE_START;
  hadc1.Init.ExternalTrigConvEdge = ADC_EXTERNALTRIGCONVEDGE_NONE;
  hadc1.Init.DMAContinuousRequests = ENABLE;
  hadc1.Init.Overrun = ADC_OVR_DATA_PRESERVED;
  hadc1.Init.OversamplingMode = ENABLE;
  hadc1.Init.Oversampling.Ratio = ADC_OVERSAMPLING_RATIO_16;
  hadc1.Init.Oversampling.RightBitShift = ADC_RIGHTBITSHIFT_4;
  hadc1.Init.Oversampling.TriggeredMode = ADC_TRIGGEREDMODE_SINGLE_TRIGGER;
  hadc1.Init.Oversampling.OversamplingStopReset = ADC_REGOVERSAMPLING_CONTINUED_MODE;
  if (HAL_ADC_Init(&hadc1) != HAL_OK)
  {
    Error_Handler();
  }

  /** Configure the ADC multi-mode
  */
  multimode.Mode = ADC_MODE_INDEPENDENT;
  if (HAL_ADCEx_MultiModeConfigChannel(&hadc1, &multimode) != HAL_OK)
  {
    Error_Handler();
  }

  /** Configure Regular Channel
  */
  sConfig.Channel = ADC_CHANNEL_VOPAMP1;
  sConfig.Rank = ADC_REGULAR_RANK_1;
  sConfig.SamplingTime = ADC_SAMPLETIME_247CYCLES_5;
  sConfig.SingleDiff = ADC_SINGLE_ENDED;
  sConfig.OffsetNumber = ADC_OFFSET_NONE;
  sConfig.Offset = 0;
  if (HAL_ADC_ConfigChannel(&hadc1, &sConfig) != HAL_OK)
  {
    Error_Handler();
  }

}

static void MX_ADC2_Init(void)
{

  ADC_ChannelConfTypeDef sConfig = {0};

  /** Common config
  */
  hadc2.Instance = ADC2;
  hadc2.Init.ClockPrescaler = ADC_CLOCK_SYNC_PCLK_DIV2;
  hadc2.Init.Resolution = ADC_RESOLUTION_12B;
  hadc2.Init.DataAlign = ADC_DATAALIGN_RIGHT;
  hadc2.Init.GainCompensation = 0;
  hadc2.Init.ScanConvMode = ADC_SCAN_DISABLE;
  hadc2.Init.EOCSelection = ADC_EOC_SINGLE_CONV;
  hadc2.Init.LowPowerAutoWait = DISABLE;
  hadc2.Init.ContinuousConvMode = ENABLE;
  hadc2.Init.NbrOfConversion = 1;
  hadc2.Init.DiscontinuousConvMode = DISABLE;
  hadc2.Init.ExternalTrigConv = ADC_SOFTWARE_START;
  hadc2.Init.ExternalTrigConvEdge = ADC_EXTERNALTRIGCONVEDGE_NONE;
  hadc2.Init.DMAContinuousRequests = ENABLE;
  hadc2.Init.Overrun = ADC_OVR_DATA_PRESERVED;
  hadc2.Init.OversamplingMode = ENABLE;
  hadc2.Init.Oversampling.Ratio = ADC_OVERSAMPLING_RATIO_16;
  hadc2.Init.Oversampling.RightBitShift = ADC_RIGHTBITSHIFT_4;
  hadc2.Init.Oversampling.TriggeredMode = ADC_TRIGGEREDMODE_SINGLE_TRIGGER;
  hadc2.Init.Oversampling.OversamplingStopReset = ADC_REGOVERSAMPLING_CONTINUED_MODE;
  if (HAL_ADC_Init(&hadc2) != HAL_OK)
  {
    Error_Handler();
  }

  /** Configure Regular Channel
  */
  sConfig.Channel = ADC_CHANNEL_VOPAMP2;
  sConfig.Rank = ADC_REGULAR_RANK_1;
  sConfig.SamplingTime = ADC_SAMPLETIME_247CYCLES_5;
  sConfig.SingleDiff = ADC_SINGLE_ENDED;
  sConfig.OffsetNumber = ADC_OFFSET_NONE;
  sConfig.Offset = 0;
  if (HAL_ADC_ConfigChannel(&hadc2, &sConfig) != HAL_OK)
  {
    Error_Handler();
  }

}

static void MX_ADC3_Init(void)
{

  ADC_MultiModeTypeDef multimode = {0};
  ADC_ChannelConfTypeDef sConfig = {0};

  /** Common config
  */
  hadc3.Instance = ADC3;
  hadc3.Init.ClockPrescaler = ADC_CLOCK_SYNC_PCLK_DIV2;
  hadc3.Init.Resolution = ADC_RESOLUTION_12B;
  hadc3.Init.DataAlign = ADC_DATAALIGN_RIGHT;
  hadc3.Init.GainCompensation = 0;
  hadc3.Init.ScanConvMode = ADC_SCAN_DISABLE;
  hadc3.Init.EOCSelection = ADC_EOC_SEQ_CONV;
  hadc3.Init.LowPowerAutoWait = DISABLE;
  hadc3.Init.ContinuousConvMode = ENABLE;
  hadc3.Init.NbrOfConversion = 1;
  hadc3.Init.DiscontinuousConvMode = DISABLE;
  hadc3.Init.ExternalTrigConv = ADC_SOFTWARE_START;
  hadc3.Init.ExternalTrigConvEdge = ADC_EXTERNALTRIGCONVEDGE_NONE;
  hadc3.Init.DMAContinuousRequests = ENABLE;
  hadc3.Init.Overrun = ADC_OVR_DATA_PRESERVED;
  hadc3.Init.OversamplingMode = ENABLE;
  hadc3.Init.Oversampling.Ratio = ADC_OVERSAMPLING_RATIO_16;
  hadc3.Init.Oversampling.RightBitShift = ADC_RIGHTBITSHIFT_4;
  hadc3.Init.Oversampling.TriggeredMode = ADC_TRIGGEREDMODE_SINGLE_TRIGGER;
  hadc3.Init.Oversampling.OversamplingStopReset = ADC_REGOVERSAMPLING_CONTINUED_MODE;
  if (HAL_ADC_Init(&hadc3) != HAL_OK)
  {
    Error_Handler();
  }

  /** Configure the ADC multi-mode
  */
  multimode.Mode = ADC_MODE_INDEPENDENT;
  if (HAL_ADCEx_MultiModeConfigChannel(&hadc3, &multimode) != HAL_OK)
  {
    Error_Handler();
  }

  /** Configure Regular Channel
  */
  sConfig.Channel = ADC_CHANNEL_VOPAMP3_ADC3;
  sConfig.Rank = ADC_REGULAR_RANK_1;
  sConfig.SamplingTime = ADC_SAMPLETIME_247CYCLES_5;
  sConfig.SingleDiff = ADC_SINGLE_ENDED;
  sConfig.OffsetNumber = ADC_OFFSET_NONE;
  sConfig.Offset = 0;
  if (HAL_ADC_ConfigChannel(&hadc3, &sConfig) != HAL_OK)
  {
    Error_Handler();
  }

}

static void MX_ADC4_Init(void)
{

  ADC_ChannelConfTypeDef sConfig = {0};

  /** Common config
  */
  hadc4.Instance = ADC4;
  hadc4.Init.ClockPrescaler = ADC_CLOCK_SYNC_PCLK_DIV2;
  hadc4.Init.Resolution = ADC_RESOLUTION_12B;
  hadc4.Init.DataAlign = ADC_DATAALIGN_RIGHT;
  hadc4.Init.GainCompensation = 0;
  hadc4.Init.ScanConvMode = ADC_SCAN_ENABLE;
  hadc4.Init.EOCSelection = ADC_EOC_SEQ_CONV;
  hadc4.Init.LowPowerAutoWait = DISABLE;
  hadc4.Init.ContinuousConvMode = ENABLE;
  hadc4.Init.NbrOfConversion = 2;
  hadc4.Init.DiscontinuousConvMode = DISABLE;
  hadc4.Init.ExternalTrigConv = ADC_SOFTWARE_START;
  hadc4.Init.ExternalTrigConvEdge = ADC_EXTERNALTRIGCONVEDGE_NONE;
  hadc4.Init.DMAContinuousRequests = ENABLE;
  hadc4.Init.Overrun = ADC_OVR_DATA_PRESERVED;
  hadc4.Init.OversamplingMode = ENABLE;
  hadc4.Init.Oversampling.Ratio = ADC_OVERSAMPLING_RATIO_16;
  hadc4.Init.Oversampling.RightBitShift = ADC_RIGHTBITSHIFT_4;
  hadc4.Init.Oversampling.TriggeredMode = ADC_TRIGGEREDMODE_SINGLE_TRIGGER;
  hadc4.Init.Oversampling.OversamplingStopReset = ADC_REGOVERSAMPLING_CONTINUED_MODE;
  if (HAL_ADC_Init(&hadc4) != HAL_OK)
  {
    Error_Handler();
  }

  /** Configure Regular Channel
  */
  sConfig.Channel = ADC_CHANNEL_VREFINT;
  sConfig.Rank = ADC_REGULAR_RANK_1;
  sConfig.SamplingTime = ADC_SAMPLETIME_247CYCLES_5;
  sConfig.SingleDiff = ADC_SINGLE_ENDED;
  sConfig.OffsetNumber = ADC_OFFSET_NONE;
  sConfig.Offset = 0;
  if (HAL_ADC_ConfigChannel(&hadc4, &sConfig) != HAL_OK)
  {
    Error_Handler();
  }

  /** Configure Regular Channel
  */
  sConfig.Channel = ADC_CHANNEL_3;
  sConfig.Rank = ADC_REGULAR_RANK_2;
  if (HAL_ADC_ConfigChannel(&hadc4, &sConfig) != HAL_OK)
  {
    Error_Handler();
  }

}

static void MX_I2C1_Init(void)
{

  hi2c1.Instance = I2C1;
  hi2c1.Init.Timing = 0x20B17DB6;
  hi2c1.Init.OwnAddress1 = 0;
  hi2c1.Init.AddressingMode = I2C_ADDRESSINGMODE_7BIT;
  hi2c1.Init.DualAddressMode = I2C_DUALADDRESS_DISABLE;
  hi2c1.Init.OwnAddress2 = 0;
  hi2c1.Init.OwnAddress2Masks = I2C_OA2_NOMASK;
  hi2c1.Init.GeneralCallMode = I2C_GENERALCALL_DISABLE;
  hi2c1.Init.NoStretchMode = I2C_NOSTRETCH_DISABLE;
  if (HAL_I2C_Init(&hi2c1) != HAL_OK)
  {
    Error_Handler();
  }

  /** Configure Analogue filter
  */
  if (HAL_I2CEx_ConfigAnalogFilter(&hi2c1, I2C_ANALOGFILTER_ENABLE) != HAL_OK)
  {
    Error_Handler();
  }

  /** Configure Digital filter
  */
  if (HAL_I2CEx_ConfigDigitalFilter(&hi2c1, 0) != HAL_OK)
  {
    Error_Handler();
  }

}

static void MX_IWDG_Init(void)
{

  hiwdg.Instance = IWDG;
  hiwdg.Init.Prescaler = IWDG_PRESCALER_64;
  hiwdg.Init.Window = 4095;
  hiwdg.Init.Reload = 2999;
  if (HAL_IWDG_Init(&hiwdg) != HAL_OK)
  {
    Error_Handler();
  }

}

static void MX_OPAMP1_Init(void)
{

  hopamp1.Instance = OPAMP1;
  hopamp1.Init.PowerMode = OPAMP_POWERMODE_NORMALSPEED;
  hopamp1.Init.Mode = OPAMP_PGA_MODE;
  hopamp1.Init.NonInvertingInput = OPAMP_NONINVERTINGINPUT_IO0;
  hopamp1.Init.InternalOutput = ENABLE;
  hopamp1.Init.TimerControlledMuxmode = OPAMP_TIMERCONTROLLEDMUXMODE_DISABLE;
  hopamp1.Init.PgaConnect = OPAMP_PGA_CONNECT_INVERTINGINPUT_NO;
  hopamp1.Init.PgaGain = OPAMP_PGA_GAIN_16_OR_MINUS_15;
  hopamp1.Init.UserTrimming = OPAMP_TRIMMING_FACTORY;
  if (HAL_OPAMP_Init(&hopamp1) != HAL_OK)
  {
    Error_Handler();
  }

}

static void MX_OPAMP2_Init(void)
{

  hopamp2.Instance = OPAMP2;
  hopamp2.Init.PowerMode = OPAMP_POWERMODE_NORMALSPEED;
  hopamp2.Init.Mode = OPAMP_PGA_MODE;
  hopamp2.Init.NonInvertingInput = OPAMP_NONINVERTINGINPUT_IO0;
  hopamp2.Init.InternalOutput = ENABLE;
  hopamp2.Init.TimerControlledMuxmode = OPAMP_TIMERCONTROLLEDMUXMODE_DISABLE;
  hopamp2.Init.PgaConnect = OPAMP_PGA_CONNECT_INVERTINGINPUT_NO;
  hopamp2.Init.PgaGain = OPAMP_PGA_GAIN_16_OR_MINUS_15;
  hopamp2.Init.UserTrimming = OPAMP_TRIMMING_FACTORY;
  if (HAL_OPAMP_Init(&hopamp2) != HAL_OK)
  {
    Error_Handler();
  }

}

static void MX_OPAMP3_Init(void)
{

  hopamp3.Instance = OPAMP3;
  hopamp3.Init.PowerMode = OPAMP_POWERMODE_NORMALSPEED;
  hopamp3.Init.Mode = OPAMP_PGA_MODE;
  hopamp3.Init.NonInvertingInput = OPAMP_NONINVERTINGINPUT_IO0;
  hopamp3.Init.InternalOutput = ENABLE;
  hopamp3.Init.TimerControlledMuxmode = OPAMP_TIMERCONTROLLEDMUXMODE_DISABLE;
  hopamp3.Init.PgaConnect = OPAMP_PGA_CONNECT_INVERTINGINPUT_NO;
  hopamp3.Init.PgaGain = OPAMP_PGA_GAIN_16_OR_MINUS_15;
  hopamp3.Init.UserTrimming = OPAMP_TRIMMING_FACTORY;
  if (HAL_OPAMP_Init(&hopamp3) != HAL_OK)
  {
    Error_Handler();
  }

}

static void MX_SPI1_Init(void)
{

  /* SPI1 parameter configuration*/
  hspi1.Instance = SPI1;
  hspi1.Init.Mode = SPI_MODE_MASTER;
  hspi1.Init.Direction = SPI_DIRECTION_2LINES;
  hspi1.Init.DataSize = SPI_DATASIZE_8BIT;
  hspi1.Init.CLKPolarity = SPI_POLARITY_HIGH;
  hspi1.Init.CLKPhase = SPI_PHASE_2EDGE;
  hspi1.Init.NSS = SPI_NSS_SOFT;
  hspi1.Init.BaudRatePrescaler = SPI_BAUDRATEPRESCALER_2;
  hspi1.Init.FirstBit = SPI_FIRSTBIT_MSB;
  hspi1.Init.TIMode = SPI_TIMODE_DISABLE;
  hspi1.Init.CRCCalculation = SPI_CRCCALCULATION_DISABLE;
  hspi1.Init.CRCPolynomial = 7;
  hspi1.Init.CRCLength = SPI_CRC_LENGTH_DATASIZE;
  hspi1.Init.NSSPMode = SPI_NSS_PULSE_DISABLE;
  if (HAL_SPI_Init(&hspi1) != HAL_OK)
  {
    Error_Handler();
  }

}

static void MX_SPI2_Init(void)
{

  /* SPI2 parameter configuration*/
  hspi2.Instance = SPI2;
  hspi2.Init.Mode = SPI_MODE_MASTER;
  hspi2.Init.Direction = SPI_DIRECTION_2LINES;
  hspi2.Init.DataSize = SPI_DATASIZE_8BIT;
  hspi2.Init.CLKPolarity = SPI_POLARITY_HIGH;
  hspi2.Init.CLKPhase = SPI_PHASE_2EDGE;
  hspi2.Init.NSS = SPI_NSS_SOFT;
  hspi2.Init.BaudRatePrescaler = SPI_BAUDRATEPRESCALER_4;
  hspi2.Init.FirstBit = SPI_FIRSTBIT_MSB;
  hspi2.Init.TIMode = SPI_TIMODE_DISABLE;
  hspi2.Init.CRCCalculation = SPI_CRCCALCULATION_DISABLE;
  hspi2.Init.CRCPolynomial = 7;
  hspi2.Init.CRCLength = SPI_CRC_LENGTH_DATASIZE;
  hspi2.Init.NSSPMode = SPI_NSS_PULSE_DISABLE;
  if (HAL_SPI_Init(&hspi2) != HAL_OK)
  {
    Error_Handler();
  }

}

static void MX_TIM1_Init(void)
{

  TIM_ClockConfigTypeDef sClockSourceConfig = {0};
  TIM_MasterConfigTypeDef sMasterConfig = {0};

  htim1.Instance = TIM1;
  htim1.Init.Prescaler = 0;
  htim1.Init.CounterMode = TIM_COUNTERMODE_UP;
  htim1.Init.Period = 65535;
  htim1.Init.ClockDivision = TIM_CLOCKDIVISION_DIV1;
  htim1.Init.RepetitionCounter = 0;
  htim1.Init.AutoReloadPreload = TIM_AUTORELOAD_PRELOAD_DISABLE;
  if (HAL_TIM_Base_Init(&htim1) != HAL_OK)
  {
    Error_Handler();
  }
  sClockSourceConfig.ClockSource = TIM_CLOCKSOURCE_INTERNAL;
  if (HAL_TIM_ConfigClockSource(&htim1, &sClockSourceConfig) != HAL_OK)
  {
    Error_Handler();
  }
  sMasterConfig.MasterOutputTrigger = TIM_TRGO_RESET;
  sMasterConfig.MasterOutputTrigger2 = TIM_TRGO2_RESET;
  sMasterConfig.MasterSlaveMode = TIM_MASTERSLAVEMODE_DISABLE;
  if (HAL_TIMEx_MasterConfigSynchronization(&htim1, &sMasterConfig) != HAL_OK)
  {
    Error_Handler();
  }

}

static void MX_TIM2_Init(void)
{

  TIM_ClockConfigTypeDef sClockSourceConfig = {0};
  TIM_MasterConfigTypeDef sMasterConfig = {0};
  TIM_OC_InitTypeDef sConfigOC = {0};

  htim2.Instance = TIM2;
  htim2.Init.Prescaler = 0;
  htim2.Init.CounterMode = TIM_COUNTERMODE_UP;
  htim2.Init.Period = 4799;
  htim2.Init.ClockDivision = TIM_CLOCKDIVISION_DIV1;
  htim2.Init.AutoReloadPreload = TIM_AUTORELOAD_PRELOAD_ENABLE;
  if (HAL_TIM_Base_Init(&htim2) != HAL_OK)
  {
    Error_Handler();
  }
  sClockSourceConfig.ClockSource = TIM_CLOCKSOURCE_INTERNAL;
  if (HAL_TIM_ConfigClockSource(&htim2, &sClockSourceConfig) != HAL_OK)
  {
    Error_Handler();
  }
  if (HAL_TIM_PWM_Init(&htim2) != HAL_OK)
  {
    Error_Handler();
  }
  sMasterConfig.MasterOutputTrigger = TIM_TRGO_RESET;
  sMasterConfig.MasterSlaveMode = TIM_MASTERSLAVEMODE_DISABLE;
  if (HAL_TIMEx_MasterConfigSynchronization(&htim2, &sMasterConfig) != HAL_OK)
  {
    Error_Handler();
  }
  sConfigOC.OCMode = TIM_OCMODE_PWM1;
  sConfigOC.Pulse = 0;
  sConfigOC.OCPolarity = TIM_OCPOLARITY_HIGH;
  sConfigOC.OCFastMode = TIM_OCFAST_DISABLE;
  if (HAL_TIM_PWM_ConfigChannel(&htim2, &sConfigOC, TIM_CHANNEL_3) != HAL_OK)
  {
    Error_Handler();
  }
  HAL_TIM_MspPostInit(&htim2);

}

static void MX_TIM3_Init(void)
{

  TIM_ClockConfigTypeDef sClockSourceConfig = {0};
  TIM_MasterConfigTypeDef sMasterConfig = {0};

  htim3.Instance = TIM3;
  htim3.Init.Prescaler = 0;
  htim3.Init.CounterMode = TIM_COUNTERMODE_UP;
  htim3.Init.Period = 65535;
  htim3.Init.ClockDivision = TIM_CLOCKDIVISION_DIV1;
  htim3.Init.AutoReloadPreload = TIM_AUTORELOAD_PRELOAD_DISABLE;
  if (HAL_TIM_Base_Init(&htim3) != HAL_OK)
  {
    Error_Handler();
  }
  sClockSourceConfig.ClockSource = TIM_CLOCKSOURCE_INTERNAL;
  if (HAL_TIM_ConfigClockSource(&htim3, &sClockSourceConfig) != HAL_OK)
  {
    Error_Handler();
  }
  sMasterConfig.MasterOutputTrigger = TIM_TRGO_RESET;
  sMasterConfig.MasterSlaveMode = TIM_MASTERSLAVEMODE_DISABLE;
  if (HAL_TIMEx_MasterConfigSynchronization(&htim3, &sMasterConfig) != HAL_OK)
  {
    Error_Handler();
  }

}

static void MX_TIM5_Init(void)
{

  TIM_ClockConfigTypeDef sClockSourceConfig = {0};
  TIM_MasterConfigTypeDef sMasterConfig = {0};
  TIM_OC_InitTypeDef sConfigOC = {0};

  htim5.Instance = TIM5;
  htim5.Init.Prescaler = 0;
  htim5.Init.CounterMode = TIM_COUNTERMODE_UP;
  htim5.Init.Period = 4294967295;
  htim5.Init.ClockDivision = TIM_CLOCKDIVISION_DIV1;
  htim5.Init.AutoReloadPreload = TIM_AUTORELOAD_PRELOAD_DISABLE;
  if (HAL_TIM_Base_Init(&htim5) != HAL_OK)
  {
    Error_Handler();
  }
  sClockSourceConfig.ClockSource = TIM_CLOCKSOURCE_INTERNAL;
  if (HAL_TIM_ConfigClockSource(&htim5, &sClockSourceConfig) != HAL_OK)
  {
    Error_Handler();
  }
  if (HAL_TIM_PWM_Init(&htim5) != HAL_OK)
  {
    Error_Handler();
  }
  sMasterConfig.MasterOutputTrigger = TIM_TRGO_RESET;
  sMasterConfig.MasterSlaveMode = TIM_MASTERSLAVEMODE_DISABLE;
  if (HAL_TIMEx_MasterConfigSynchronization(&htim5, &sMasterConfig) != HAL_OK)
  {
    Error_Handler();
  }
  sConfigOC.OCMode = TIM_OCMODE_PWM1;
  sConfigOC.Pulse = 0;
  sConfigOC.OCPolarity = TIM_OCPOLARITY_HIGH;
  sConfigOC.OCFastMode = TIM_OCFAST_DISABLE;
  if (HAL_TIM_PWM_ConfigChannel(&htim5, &sConfigOC, TIM_CHANNEL_1) != HAL_OK)
  {
    Error_Handler();
  }
  HAL_TIM_MspPostInit(&htim5);

}

static void MX_TIM6_Init(void)
{

  TIM_MasterConfigTypeDef sMasterConfig = {0};

  htim6.Instance = TIM6;
  htim6.Init.Prescaler = 95;
  htim6.Init.CounterMode = TIM_COUNTERMODE_UP;
  htim6.Init.Period = 65535;
  htim6.Init.AutoReloadPreload = TIM_AUTORELOAD_PRELOAD_ENABLE;
  if (HAL_TIM_Base_Init(&htim6) != HAL_OK)
  {
    Error_Handler();
  }
  sMasterConfig.MasterOutputTrigger = TIM_TRGO_RESET;
  sMasterConfig.MasterSlaveMode = TIM_MASTERSLAVEMODE_DISABLE;
  if (HAL_TIMEx_MasterConfigSynchronization(&htim6, &sMasterConfig) != HAL_OK)
  {
    Error_Handler();
  }
  /* USER CODE BEGIN TIM6_Init 2 */
  /* Override CubeMX period: 96MHz / (96 * 1000) = 1000 Hz exactly */
  htim6.Init.Period = 999;
  HAL_TIM_Base_Init(&htim6);
  /* USER CODE END TIM6_Init 2 */

}

static void MX_DMA_Init(void)
{

  /* DMA controller clock enable */
  __HAL_RCC_DMAMUX1_CLK_ENABLE();
  __HAL_RCC_DMA1_CLK_ENABLE();

  /* DMA interrupt init */
  /* DMA1_Channel1_IRQn interrupt configuration */
  HAL_NVIC_SetPriority(DMA1_Channel1_IRQn, 0, 0);
  HAL_NVIC_EnableIRQ(DMA1_Channel1_IRQn);
  /* DMA1_Channel4_IRQn interrupt configuration */
  HAL_NVIC_SetPriority(DMA1_Channel4_IRQn, 0, 0);
  HAL_NVIC_EnableIRQ(DMA1_Channel4_IRQn);
  /* DMA1_Channel5_IRQn interrupt configuration */
  HAL_NVIC_SetPriority(DMA1_Channel5_IRQn, 0, 0);
  HAL_NVIC_EnableIRQ(DMA1_Channel5_IRQn);
  /* DMA1_Channel6_IRQn interrupt configuration */
  HAL_NVIC_SetPriority(DMA1_Channel6_IRQn, 0, 0);
  HAL_NVIC_EnableIRQ(DMA1_Channel6_IRQn);
  /* DMA1_Channel7_IRQn interrupt configuration */
  HAL_NVIC_SetPriority(DMA1_Channel7_IRQn, 0, 0);
  HAL_NVIC_EnableIRQ(DMA1_Channel7_IRQn);

}

static void MX_GPIO_Init(void)
{
  GPIO_InitTypeDef GPIO_InitStruct = {0};

  /* GPIO Ports Clock Enable */
  __HAL_RCC_GPIOC_CLK_ENABLE();
  __HAL_RCC_GPIOF_CLK_ENABLE();
  __HAL_RCC_GPIOG_CLK_ENABLE();
  __HAL_RCC_GPIOA_CLK_ENABLE();
  __HAL_RCC_GPIOB_CLK_ENABLE();

  /*Configure GPIO pin Output Level */
  HAL_GPIO_WritePin(GPIOA, TFT_CS_Pin|TFT_DC_Pin|TFT_RST_Pin, GPIO_PIN_SET);

  /*Configure GPIO pin Output Level */
  HAL_GPIO_WritePin(FL_CS_GPIO_Port, FL_CS_Pin, GPIO_PIN_SET);

  /*Configure GPIO pins : PC13 PC14 PC15 */
  GPIO_InitStruct.Pin = GPIO_PIN_13|GPIO_PIN_14|GPIO_PIN_15;
  GPIO_InitStruct.Mode = GPIO_MODE_ANALOG;
  GPIO_InitStruct.Pull = GPIO_NOPULL;
  HAL_GPIO_Init(GPIOC, &GPIO_InitStruct);

  /*Configure GPIO pins : PF0 PF1 */
  GPIO_InitStruct.Pin = GPIO_PIN_0|GPIO_PIN_1;
  GPIO_InitStruct.Mode = GPIO_MODE_ANALOG;
  GPIO_InitStruct.Pull = GPIO_NOPULL;
  HAL_GPIO_Init(GPIOF, &GPIO_InitStruct);

  /*Configure GPIO pin : PG10 */
  GPIO_InitStruct.Pin = GPIO_PIN_10;
  GPIO_InitStruct.Mode = GPIO_MODE_ANALOG;
  GPIO_InitStruct.Pull = GPIO_NOPULL;
  HAL_GPIO_Init(GPIOG, &GPIO_InitStruct);

  /*Configure GPIO pins : BTN_M_Pin BTN_S_Pin */
  GPIO_InitStruct.Pin = BTN_M_Pin|BTN_S_Pin;
  GPIO_InitStruct.Mode = GPIO_MODE_INPUT;
  GPIO_InitStruct.Pull = GPIO_PULLDOWN;
  HAL_GPIO_Init(GPIOA, &GPIO_InitStruct);

  /*Configure GPIO pins : PA4 PA6 PA8 */
  GPIO_InitStruct.Pin = GPIO_PIN_4|GPIO_PIN_6|GPIO_PIN_8;
  GPIO_InitStruct.Mode = GPIO_MODE_ANALOG;
  GPIO_InitStruct.Pull = GPIO_NOPULL;
  HAL_GPIO_Init(GPIOA, &GPIO_InitStruct);

  /*Configure GPIO pins : PB1 PB2 PB10 PB11
                           PB14 PB3 PB8 PB9 */
  GPIO_InitStruct.Pin = GPIO_PIN_1|GPIO_PIN_2|GPIO_PIN_10|GPIO_PIN_11
                          |GPIO_PIN_14|GPIO_PIN_3|GPIO_PIN_8|GPIO_PIN_9;
  GPIO_InitStruct.Mode = GPIO_MODE_ANALOG;
  GPIO_InitStruct.Pull = GPIO_NOPULL;
  HAL_GPIO_Init(GPIOB, &GPIO_InitStruct);

  /*Configure GPIO pins : TFT_CS_Pin TFT_DC_Pin */
  GPIO_InitStruct.Pin = TFT_CS_Pin|TFT_DC_Pin;
  GPIO_InitStruct.Mode = GPIO_MODE_OUTPUT_PP;
  GPIO_InitStruct.Pull = GPIO_NOPULL;
  GPIO_InitStruct.Speed = GPIO_SPEED_FREQ_VERY_HIGH;
  HAL_GPIO_Init(GPIOA, &GPIO_InitStruct);

  /*Configure GPIO pin : TFT_RST_Pin */
  GPIO_InitStruct.Pin = TFT_RST_Pin;
  GPIO_InitStruct.Mode = GPIO_MODE_OUTPUT_PP;
  GPIO_InitStruct.Pull = GPIO_PULLUP;
  GPIO_InitStruct.Speed = GPIO_SPEED_FREQ_VERY_HIGH;
  HAL_GPIO_Init(TFT_RST_GPIO_Port, &GPIO_InitStruct);

  /*Configure GPIO pin : FL_CS_Pin */
  GPIO_InitStruct.Pin = FL_CS_Pin;
  GPIO_InitStruct.Mode = GPIO_MODE_OUTPUT_PP;
  GPIO_InitStruct.Pull = GPIO_PULLUP;
  GPIO_InitStruct.Speed = GPIO_SPEED_FREQ_VERY_HIGH;
  HAL_GPIO_Init(FL_CS_GPIO_Port, &GPIO_InitStruct);

  /* USER CODE BEGIN MX_GPIO_Init_2 */
  /* Reconfigure BTN_M (PA2) and BTN_S (PA3) as rising-edge EXTI inputs */
  GPIO_InitStruct.Pin = GPIO_PIN_2 | GPIO_PIN_3;
  GPIO_InitStruct.Mode = GPIO_MODE_IT_RISING;
  HAL_GPIO_Init(GPIOA, &GPIO_InitStruct);
  HAL_NVIC_SetPriority(EXTI2_IRQn, 2, 0);
  HAL_NVIC_EnableIRQ(EXTI2_IRQn);
  HAL_NVIC_SetPriority(EXTI3_IRQn, 2, 0);
  HAL_NVIC_EnableIRQ(EXTI3_IRQn);
  /* USER CODE END MX_GPIO_Init_2 */
}

/* USER CODE BEGIN 4 */

/**
 * @brief Vibro motor hardware test — exercises PA0 (TIM5 CH1 PWM) at
 *        various pulse lengths and duty cycles.
 *        Call manually in USER CODE BEGIN 2 when debugging hardware.
 *
 * Timer maths: 96 MHz / (PSC+1=960) = 100 kHz tick; ARR+1=500 → 200 Hz PWM.
 * CCR1 sets pulse width: CCR1/500 = duty cycle (0..499).
 */
void vibro_motor_test(void)
{
    /* 200 Hz PWM: 96 MHz / 960 / 500 = 200 Hz */
    __HAL_TIM_SET_PRESCALER(&htim5, 959);
    __HAL_TIM_SET_AUTORELOAD(&htim5, 499);

    /* Short burst – 25% duty, 300 ms */
    __HAL_TIM_SET_COMPARE(&htim5, TIM_CHANNEL_1, 124);
    HAL_TIM_PWM_Start(&htim5, TIM_CHANNEL_1);
    HAL_Delay(300);
    HAL_TIM_PWM_Stop(&htim5, TIM_CHANNEL_1);
    HAL_Delay(300);

    /* Medium burst – 50% duty, 500 ms */
    __HAL_TIM_SET_COMPARE(&htim5, TIM_CHANNEL_1, 249);
    HAL_TIM_PWM_Start(&htim5, TIM_CHANNEL_1);
    HAL_Delay(500);
    HAL_TIM_PWM_Stop(&htim5, TIM_CHANNEL_1);
    HAL_Delay(300);

    /* Long burst – 75% duty, 800 ms */
    __HAL_TIM_SET_COMPARE(&htim5, TIM_CHANNEL_1, 374);
    HAL_TIM_PWM_Start(&htim5, TIM_CHANNEL_1);
    HAL_Delay(800);
    HAL_TIM_PWM_Stop(&htim5, TIM_CHANNEL_1);
    HAL_Delay(300);

    /* Full power – 99% duty, 1000 ms */
    __HAL_TIM_SET_COMPARE(&htim5, TIM_CHANNEL_1, 494);
    HAL_TIM_PWM_Start(&htim5, TIM_CHANNEL_1);
    HAL_Delay(1000);
    HAL_TIM_PWM_Stop(&htim5, TIM_CHANNEL_1);
}

/* USER CODE END 4 */

void Error_Handler(void)
{
  /* USER CODE BEGIN Error_Handler_Debug */
  /* User can add his own implementation to report the HAL error return state */
  __disable_irq();
  while (1)
  {
	  system_shutdown();
  }
  /* USER CODE END Error_Handler_Debug */
}
